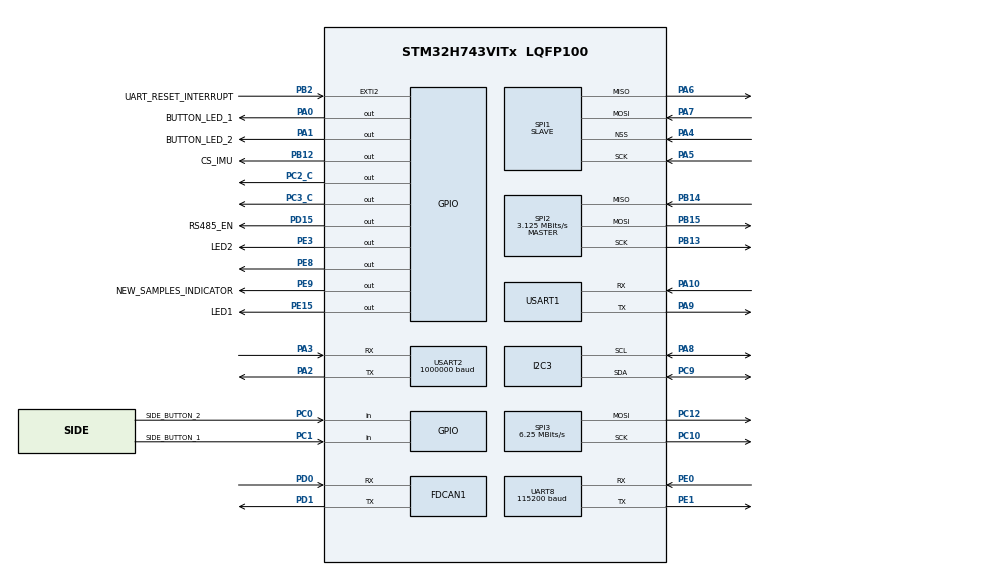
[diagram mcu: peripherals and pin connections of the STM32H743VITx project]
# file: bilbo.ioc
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CORTEX_M7.default_mode_Activation=0
Dma.MEMTOMEM.6.Direction=DMA_MEMORY_TO_MEMORY
Dma.MEMTOMEM.6.EventEnable=DISABLE
Dma.MEMTOMEM.6.FIFOMode=DMA_FIFOMODE_ENABLE
Dma.MEMTOMEM.6.FIFOThreshold=DMA_FIFO_THRESHOLD_FULL
Dma.MEMTOMEM.6.Instance=DMA2_Stream0
Dma.MEMTOMEM.6.MemBurst=DMA_MBURST_SINGLE
Dma.MEMTOMEM.6.MemDataAlignment=DMA_MDATAALIGN_BYTE
Dma.MEMTOMEM.6.MemInc=DMA_MINC_ENABLE
Dma.MEMTOMEM.6.Mode=DMA_NORMAL
Dma.MEMTOMEM.6.PeriphBurst=DMA_PBURST_SINGLE
Dma.MEMTOMEM.6.PeriphDataAlignment=DMA_PDATAALIGN_BYTE
Dma.MEMTOMEM.6.PeriphInc=DMA_PINC_ENABLE
Dma.MEMTOMEM.6.Polarity=HAL_DMAMUX_REQ_GEN_RISING
Dma.MEMTOMEM.6.Priority=DMA_PRIORITY_VERY_HIGH
Dma.MEMTOMEM.6.RequestNumber=1
Dma.MEMTOMEM.6.SignalID=NONE
Dma.MEMTOMEM.6.SyncEnable=DISABLE
Dma.MEMTOMEM.6.SyncPolarity=HAL_DMAMUX_SYNC_NO_EVENT
Dma.MEMTOMEM.6.SyncRequestNumber=1
Dma.MEMTOMEM.6.SyncSignalID=NONE
Dma.MEMTOMEM.9.Direction=DMA_MEMORY_TO_MEMORY
Dma.MEMTOMEM.9.EventEnable=DISABLE
Dma.MEMTOMEM.9.FIFOMode=DMA_FIFOMODE_ENABLE
Dma.MEMTOMEM.9.FIFOThreshold=DMA_FIFO_THRESHOLD_FULL
Dma.MEMTOMEM.9.Instance=DMA2_Stream1
Dma.MEMTOMEM.9.MemBurst=DMA_MBURST_SINGLE
Dma.MEMTOMEM.9.MemDataAlignment=DMA_MDATAALIGN_BYTE
Dma.MEMTOMEM.9.MemInc=DMA_MINC_ENABLE
Dma.MEMTOMEM.9.Mode=DMA_NORMAL
Dma.MEMTOMEM.9.PeriphBurst=DMA_PBURST_SINGLE
Dma.MEMTOMEM.9.PeriphDataAlignment=DMA_PDATAALIGN_BYTE
Dma.MEMTOMEM.9.PeriphInc=DMA_PINC_ENABLE
Dma.MEMTOMEM.9.Polarity=HAL_DMAMUX_REQ_GEN_RISING
Dma.MEMTOMEM.9.Priority=DMA_PRIORITY_HIGH
Dma.MEMTOMEM.9.RequestNumber=1
Dma.MEMTOMEM.9.SignalID=NONE
Dma.MEMTOMEM.9.SyncEnable=DISABLE
Dma.MEMTOMEM.9.SyncPolarity=HAL_DMAMUX_SYNC_NO_EVENT
Dma.MEMTOMEM.9.SyncRequestNumber=1
Dma.MEMTOMEM.9.SyncSignalID=NONE
Dma.Request0=USART1_RX
Dma.Request1=USART1_TX
Dma.Request2=UART8_RX
Dma.Request3=UART8_TX
Dma.Request4=USART2_RX
Dma.Request5=USART2_TX
Dma.Request6=MEMTOMEM
Dma.Request7=SPI1_RX
Dma.Request8=SPI1_TX
Dma.Request9=MEMTOMEM
Dma.SPI1_RX.7.Direction=DMA_PERIPH_TO_MEMORY
Dma.SPI1_RX.7.EventEnable=DISABLE
Dma.SPI1_RX.7.FIFOMode=DMA_FIFOMODE_DISABLE
Dma.SPI1_RX.7.Instance=DMA1_Stream6
Dma.SPI1_RX.7.MemDataAlignment=DMA_MDATAALIGN_BYTE
Dma.SPI1_RX.7.MemInc=DMA_MINC_ENABLE
Dma.SPI1_RX.7.Mode=DMA_NORMAL
Dma.SPI1_RX.7.PeriphDataAlignment=DMA_PDATAALIGN_BYTE
Dma.SPI1_RX.7.PeriphInc=DMA_PINC_DISABLE
Dma.SPI1_RX.7.Polarity=HAL_DMAMUX_REQ_GEN_RISING
Dma.SPI1_RX.7.Priority=DMA_PRIORITY_LOW
Dma.SPI1_RX.7.RequestNumber=1
Dma.SPI1_RX.7.SignalID=NONE
Dma.SPI1_RX.7.SyncEnable=DISABLE
Dma.SPI1_RX.7.SyncPolarity=HAL_DMAMUX_SYNC_NO_EVENT
Dma.SPI1_RX.7.SyncRequestNumber=1
Dma.SPI1_RX.7.SyncSignalID=NONE
Dma.SPI1_TX.8.Direction=DMA_MEMORY_TO_PERIPH
Dma.SPI1_TX.8.EventEnable=DISABLE
Dma.SPI1_TX.8.FIFOMode=DMA_FIFOMODE_DISABLE
Dma.SPI1_TX.8.Instance=DMA1_Stream7
Dma.SPI1_TX.8.MemDataAlignment=DMA_MDATAALIGN_BYTE
Dma.SPI1_TX.8.MemInc=DMA_MINC_ENABLE
Dma.SPI1_TX.8.Mode=DMA_NORMAL
Dma.SPI1_TX.8.PeriphDataAlignment=DMA_PDATAALIGN_BYTE
Dma.SPI1_TX.8.PeriphInc=DMA_PINC_DISABLE
Dma.SPI1_TX.8.Polarity=HAL_DMAMUX_REQ_GEN_RISING
Dma.SPI1_TX.8.Priority=DMA_PRIORITY_LOW
Dma.SPI1_TX.8.RequestNumber=1
Dma.SPI1_TX.8.SignalID=NONE
Dma.SPI1_TX.8.SyncEnable=DISABLE
Dma.SPI1_TX.8.SyncPolarity=HAL_DMAMUX_SYNC_NO_EVENT
Dma.SPI1_TX.8.SyncRequestNumber=1
Dma.SPI1_TX.8.SyncSignalID=NONE
Dma.UART8_RX.2.Direction=DMA_PERIPH_TO_MEMORY
Dma.UART8_RX.2.EventEnable=DISABLE
Dma.UART8_RX.2.FIFOMode=DMA_FIFOMODE_DISABLE
Dma.UART8_RX.2.Instance=DMA1_Stream2
Dma.UART8_RX.2.MemDataAlignment=DMA_MDATAALIGN_BYTE
Dma.UART8_RX.2.MemInc=DMA_MINC_ENABLE
Dma.UART8_RX.2.Mode=DMA_NORMAL
Dma.UART8_RX.2.PeriphDataAlignment=DMA_PDATAALIGN_BYTE
Dma.UART8_RX.2.PeriphInc=DMA_PINC_DISABLE
Dma.UART8_RX.2.Polarity=HAL_DMAMUX_REQ_GEN_RISING
Dma.UART8_RX.2.Priority=DMA_PRIORITY_HIGH
Dma.UART8_RX.2.RequestNumber=1
Dma.UART8_RX.2.SignalID=NONE
Dma.UART8_RX.2.SyncEnable=DISABLE
Dma.UART8_RX.2.SyncPolarity=HAL_DMAMUX_SYNC_NO_EVENT
Dma.UART8_RX.2.SyncRequestNumber=1
Dma.UART8_RX.2.SyncSignalID=NONE
Dma.UART8_TX.3.Direction=DMA_MEMORY_TO_PERIPH
Dma.UART8_TX.3.EventEnable=DISABLE
Dma.UART8_TX.3.FIFOMode=DMA_FIFOMODE_DISABLE
Dma.UART8_TX.3.Instance=DMA1_Stream3
Dma.UART8_TX.3.MemDataAlignment=DMA_MDATAALIGN_BYTE
Dma.UART8_TX.3.MemInc=DMA_MINC_ENABLE
Dma.UART8_TX.3.Mode=DMA_NORMAL
Dma.UART8_TX.3.PeriphDataAlignment=DMA_PDATAALIGN_BYTE
Dma.UART8_TX.3.PeriphInc=DMA_PINC_DISABLE
Dma.UART8_TX.3.Polarity=HAL_DMAMUX_REQ_GEN_RISING
Dma.UART8_TX.3.Priority=DMA_PRIORITY_LOW
Dma.UART8_TX.3.RequestNumber=1
Dma.UART8_TX.3.SignalID=NONE
Dma.UART8_TX.3.SyncEnable=DISABLE
Dma.UART8_TX.3.SyncPolarity=HAL_DMAMUX_SYNC_NO_EVENT
Dma.UART8_TX.3.SyncRequestNumber=1
Dma.UART8_TX.3.SyncSignalID=NONE
Dma.USART1_RX.0.Direction=DMA_PERIPH_TO_MEMORY
Dma.USART1_RX.0.EventEnable=DISABLE
Dma.USART1_RX.0.FIFOMode=DMA_FIFOMODE_DISABLE
Dma.USART1_RX.0.Instance=DMA1_Stream0
Dma.USART1_RX.0.MemDataAlignment=DMA_MDATAALIGN_BYTE
Dma.USART1_RX.0.MemInc=DMA_MINC_ENABLE
Dma.USART1_RX.0.Mode=DMA_NORMAL
Dma.USART1_RX.0.PeriphDataAlignment=DMA_PDATAALIGN_BYTE
Dma.USART1_RX.0.PeriphInc=DMA_PINC_DISABLE
Dma.USART1_RX.0.Polarity=HAL_DMAMUX_REQ_GEN_RISING
Dma.USART1_RX.0.Priority=DMA_PRIORITY_LOW
Dma.USART1_RX.0.RequestNumber=1
Dma.USART1_RX.0.SignalID=NONE
Dma.USART1_RX.0.SyncEnable=DISABLE
Dma.USART1_RX.0.SyncPolarity=HAL_DMAMUX_SYNC_NO_EVENT
Dma.USART1_RX.0.SyncRequestNumber=1
Dma.USART1_RX.0.SyncSignalID=NONE
Dma.USART1_TX.1.Direction=DMA_MEMORY_TO_PERIPH
Dma.USART1_TX.1.EventEnable=DISABLE
Dma.USART1_TX.1.FIFOMode=DMA_FIFOMODE_DISABLE
Dma.USART1_TX.1.Instance=DMA1_Stream1
Dma.USART1_TX.1.MemDataAlignment=DMA_MDATAALIGN_BYTE
Dma.USART1_TX.1.MemInc=DMA_MINC_ENABLE
Dma.USART1_TX.1.Mode=DMA_NORMAL
Dma.USART1_TX.1.PeriphDataAlignment=DMA_PDATAALIGN_BYTE
Dma.USART1_TX.1.PeriphInc=DMA_PINC_DISABLE
Dma.USART1_TX.1.Polarity=HAL_DMAMUX_REQ_GEN_RISING
Dma.USART1_TX.1.Priority=DMA_PRIORITY_LOW
Dma.USART1_TX.1.RequestNumber=1
Dma.USART1_TX.1.SignalID=NONE
Dma.USART1_TX.1.SyncEnable=DISABLE
Dma.USART1_TX.1.SyncPolarity=HAL_DMAMUX_SYNC_NO_EVENT
Dma.USART1_TX.1.SyncRequestNumber=1
Dma.USART1_TX.1.SyncSignalID=NONE
Dma.USART2_RX.4.Direction=DMA_PERIPH_TO_MEMORY
Dma.USART2_RX.4.EventEnable=DISABLE
Dma.USART2_RX.4.FIFOMode=DMA_FIFOMODE_DISABLE
Dma.USART2_RX.4.Instance=DMA1_Stream4
Dma.USART2_RX.4.MemDataAlignment=DMA_MDATAALIGN_BYTE
Dma.USART2_RX.4.MemInc=DMA_MINC_ENABLE
Dma.USART2_RX.4.Mode=DMA_NORMAL
Dma.USART2_RX.4.PeriphDataAlignment=DMA_PDATAALIGN_BYTE
Dma.USART2_RX.4.PeriphInc=DMA_PINC_DISABLE
Dma.USART2_RX.4.Polarity=HAL_DMAMUX_REQ_GEN_RISING
Dma.USART2_RX.4.Priority=DMA_PRIORITY_LOW
Dma.USART2_RX.4.RequestNumber=1
Dma.USART2_RX.4.SignalID=NONE
Dma.USART2_RX.4.SyncEnable=DISABLE
Dma.USART2_RX.4.SyncPolarity=HAL_DMAMUX_SYNC_NO_EVENT
Dma.USART2_RX.4.SyncRequestNumber=1
Dma.USART2_RX.4.SyncSignalID=NONE
Dma.USART2_TX.5.Direction=DMA_MEMORY_TO_PERIPH
Dma.USART2_TX.5.EventEnable=DISABLE
Dma.USART2_TX.5.FIFOMode=DMA_FIFOMODE_DISABLE
Dma.USART2_TX.5.Instance=DMA1_Stream5
Dma.USART2_TX.5.MemDataAlignment=DMA_MDATAALIGN_BYTE
Dma.USART2_TX.5.MemInc=DMA_MINC_ENABLE
Dma.USART2_TX.5.Mode=DMA_NORMAL
Dma.USART2_TX.5.PeriphDataAlignment=DMA_PDATAALIGN_BYTE
Dma.USART2_TX.5.PeriphInc=DMA_PINC_DISABLE
Dma.USART2_TX.5.Polarity=HAL_DMAMUX_REQ_GEN_RISING
Dma.USART2_TX.5.Priority=DMA_PRIORITY_LOW
Dma.USART2_TX.5.RequestNumber=1
Dma.USART2_TX.5.SignalID=NONE
Dma.USART2_TX.5.SyncEnable=DISABLE
Dma.USART2_TX.5.SyncPolarity=HAL_DMAMUX_SYNC_NO_EVENT
Dma.USART2_TX.5.SyncRequestNumber=1
Dma.USART2_TX.5.SyncSignalID=NONE
FDCAN1.CalculateBaudRateNominal=1000000
FDCAN1.CalculateTimeBitNominal=1000
FDCAN1.CalculateTimeQuantumNominal=100.0
FDCAN1.FrameFormat=FDCAN_FRAME_CLASSIC
FDCAN1.NominalPrescaler=10
FDCAN1.NominalTimeSeg1=7
FDCAN1.NominalTimeSeg2=2
FDCAN1.RxFifo0ElmtsNbr=4
FDCAN1.RxFifo1ElmtsNbr=4
FDCAN1.TxBuffersNbr=28
FDCAN1.TxFifoQueueElmtsNbr=4
FREERTOS.Tasks01=defaultTask,24,128,StartDefaultTask,Default,NULL,Dynamic,NULL,NULL
FREERTOS.Timers01=myTimer02,Callback01,osTimerPeriodic,Default,NULL,Dynamic,NULL
FREERTOS.configTOTAL_HEAP_SIZE=120000
FREERTOS.configUSE_NEWLIB_REENTRANT=1
I2C3.I2C_Rise_Time=0
I2C3.Timing=0x10C0ECFF
Mcu.Family=STM32H7
Mcu.Name=STM32H743VITx
Mcu.Package=LQFP100
NVIC.DMA1_Stream0_IRQn=true\:5\:0\:false\:false\:true\:true\:false\:true\:true
NVIC.DMA1_Stream1_IRQn=true\:5\:0\:false\:false\:true\:true\:false\:true\:true
NVIC.DMA1_Stream2_IRQn=true\:5\:0\:false\:false\:true\:false\:false\:true\:true
NVIC.DMA1_Stream3_IRQn=true\:5\:0\:false\:false\:true\:true\:false\:true\:true
NVIC.DMA1_Stream4_IRQn=true\:5\:0\:false\:false\:true\:true\:false\:true\:true
NVIC.DMA1_Stream5_IRQn=true\:5\:0\:false\:false\:true\:true\:false\:true\:true
NVIC.DMA1_Stream6_IRQn=true\:5\:0\:false\:false\:true\:true\:false\:true\:true
NVIC.DMA1_Stream7_IRQn=true\:5\:0\:false\:false\:true\:true\:false\:true\:true
NVIC.DMA2_Stream0_IRQn=true\:5\:0\:false\:false\:true\:true\:true\:true\:true
NVIC.DMA2_Stream1_IRQn=true\:5\:0\:false\:false\:true\:true\:true\:true\:true
NVIC.EXTI2_IRQn=true\:5\:0\:false\:false\:true\:true\:true\:true\:true
NVIC.FDCAN1_IT0_IRQn=true\:5\:0\:false\:false\:true\:true\:true\:true\:true
NVIC.FDCAN1_IT1_IRQn=true\:5\:0\:false\:false\:true\:true\:true\:true\:true
NVIC.I2C3_ER_IRQn=true\:5\:0\:false\:false\:true\:true\:true\:true\:true
NVIC.I2C3_EV_IRQn=true\:5\:0\:false\:false\:true\:true\:true\:true\:true
NVIC.PriorityGroup=NVIC_PRIORITYGROUP_4
NVIC.SPI1_IRQn=true\:5\:0\:false\:false\:true\:true\:true\:true\:true
NVIC.TIM6_DAC_IRQn=true\:15\:0\:false\:false\:true\:false\:false\:true\:true
NVIC.TimeBase=TIM6_DAC_IRQn
NVIC.TimeBaseIP=TIM6
NVIC.UART8_IRQn=true\:5\:0\:false\:false\:true\:true\:true\:true\:true
NVIC.USART1_IRQn=true\:5\:0\:false\:false\:true\:true\:true\:true\:true
NVIC.USART2_IRQn=true\:5\:0\:false\:false\:true\:true\:true\:true\:true
PA0.GPIO_Label=BUTTON_LED_1
PA0.Signal=GPIO_Output
PA1.GPIO_Label=BUTTON_LED_2
PA1.Signal=GPIO_Output
PA10.Mode=Asynchronous
PA10.Signal=USART1_RX
PA13\ (JTMS/SWDIO).Mode=Serial_Wire
PA13\ (JTMS/SWDIO).Signal=DEBUG_JTMS-SWDIO
PA14\ (JTCK/SWCLK).Mode=Serial_Wire
PA14\ (JTCK/SWCLK).Signal=DEBUG_JTCK-SWCLK
PA2.Mode=Asynchronous
PA2.Signal=USART2_TX
PA3.Mode=Asynchronous
PA3.Signal=USART2_RX
PA4.GPIO_PuPd=GPIO_NOPULL
PA4.GPIO_Speed=GPIO_SPEED_FREQ_VERY_HIGH
PA4.Mode=NSS_Signal_Hard_Input
PA4.Signal=SPI1_NSS
PA5.GPIO_Speed=GPIO_SPEED_FREQ_VERY_HIGH
PA5.Mode=Full_Duplex_Slave
PA5.Signal=SPI1_SCK
PA6.GPIO_Speed=GPIO_SPEED_FREQ_VERY_HIGH
PA6.Mode=Full_Duplex_Slave
PA6.Signal=SPI1_MISO
PA7.GPIO_Speed=GPIO_SPEED_FREQ_VERY_HIGH
PA7.Mode=Full_Duplex_Slave
PA7.Signal=SPI1_MOSI
PA8.Mode=I2C
PA8.Signal=I2C3_SCL
PA9.Mode=Asynchronous
PA9.Signal=USART1_TX
PB12.GPIO_Label=CS_IMU
PB12.Signal=GPIO_Output
PB13.Mode=Full_Duplex_Master
PB13.Signal=SPI2_SCK
PB14.Mode=Full_Duplex_Master
PB14.Signal=SPI2_MISO
PB15.Mode=Full_Duplex_Master
PB15.Signal=SPI2_MOSI
PB2.GPIO_Label=UART_RESET_INTERRUPT
PB2.GPIO_ModeDefaultEXTI=GPIO_MODE_IT_RISING_FALLING
PB2.GPIO_PuPd=GPIO_PULLDOWN
PB2.Signal=GPXTI2
PC0.GPIO_Label=SIDE_BUTTON_2
PC0.GPIO_PuPd=GPIO_PULLUP
PC0.Signal=GPIO_Input
PC1.GPIO_Label=SIDE_BUTTON_1
PC1.GPIO_PuPd=GPIO_PULLUP
PC1.Signal=GPIO_Input
PC10.Mode=TX_Only_Simplex_Unidirect_Master
PC10.Signal=SPI3_SCK
PC12.Mode=TX_Only_Simplex_Unidirect_Master
PC12.Signal=SPI3_MOSI
PC2_C.Signal=GPIO_Output
PC3_C.Signal=GPIO_Output
PC9.Mode=I2C
PC9.Signal=I2C3_SDA
PD0.Mode=FDCAN_Activate
PD0.Signal=FDCAN1_RX
PD1.Mode=FDCAN_Activate
PD1.Signal=FDCAN1_TX
PD15.GPIO_Label=RS485_EN
PD15.Signal=GPIO_Output
PE0.Mode=Asynchronous
PE0.Signal=UART8_RX
PE1.Mode=Asynchronous
PE1.Signal=UART8_TX
PE15.GPIO_Label=LED1
PE15.Signal=GPIO_Output
PE3.GPIO_Label=LED2
PE3.Signal=GPIO_Output
PE8.Signal=GPIO_Output
PE9.GPIO_Label=NEW_SAMPLES_INDICATOR
PE9.GPIO_PuPd=GPIO_PULLDOWN
PE9.Signal=GPIO_Output
PH0-OSC_IN\ (PH0).Mode=HSE-External-Oscillator
PH0-OSC_IN\ (PH0).Signal=RCC_OSC_IN
PH1-OSC_OUT\ (PH1).Mode=HSE-External-Oscillator
PH1-OSC_OUT\ (PH1).Signal=RCC_OSC_OUT
ProjectManager.HeapSize=0x200
ProjectManager.StackSize=0x400
ProjectManager.TargetToolchain=STM32CubeIDE
RCC.ADCFreq_Value=100000000
RCC.APB1Freq_Value=100000000
RCC.APB2Freq_Value=100000000
RCC.APB3Freq_Value=100000000
RCC.APB4Freq_Value=100000000
RCC.CortexFreq_Value=400000000
RCC.D1PPRE=RCC_APB3_DIV2
RCC.D2PPRE1=RCC_APB1_DIV2
RCC.D2PPRE2=RCC_APB2_DIV2
RCC.D3PPRE=RCC_APB4_DIV2
RCC.DIVM1=2
RCC.DIVM2=2
RCC.DIVN1=64
RCC.DIVN2=64
RCC.DIVP2=8
RCC.DIVQ1=4
RCC.DIVQ2=8
RCC.FDCANCLockSelection=RCC_FDCANCLKSOURCE_PLL2
RCC.HCLKFreq_Value=200000000
RCC.HPRE=RCC_HCLK_DIV2
RCC.PLL2FRACN=0
RCC.PLLFRACN=0
RCC.PLLSourceVirtual=RCC_PLLSOURCE_HSE
RCC.PWR_Regulator_Voltage_Scale=PWR_REGULATOR_VOLTAGE_SCALE0
RCC.SYSCLKFreq_VALUE=400000000
RCC.SYSCLKSource=RCC_SYSCLKSOURCE_PLLCLK
RCC.USBFreq_Value=200000000
SPI1.DataSize=SPI_DATASIZE_8BIT
SPI1.Direction=SPI_DIRECTION_2LINES
SPI1.Mode=SPI_MODE_SLAVE
SPI1.VirtualNSS=VM_NSSHARD
SPI1.VirtualType=VM_SLAVE
SPI2.BaudRatePrescaler=SPI_BAUDRATEPRESCALER_64
SPI2.CalculateBaudRate=3.125 MBits/s
SPI2.DataSize=SPI_DATASIZE_8BIT
SPI2.Direction=SPI_DIRECTION_2LINES
SPI2.Mode=SPI_MODE_MASTER
SPI2.VirtualType=VM_MASTER
SPI3.BaudRatePrescaler=SPI_BAUDRATEPRESCALER_32
SPI3.CalculateBaudRate=6.25 MBits/s
SPI3.DataSize=SPI_DATASIZE_8BIT
SPI3.Direction=SPI_DIRECTION_2LINES_TXONLY
SPI3.Mode=SPI_MODE_MASTER
SPI3.VirtualType=VM_MASTER
UART8.BaudRate=115200
UART8.Parity=PARITY_EVEN
UART8.WordLength=WORDLENGTH_9B
USART1.VirtualMode-Asynchronous=VM_ASYNC
USART2.BaudRate=1000000
USART2.VirtualMode-Asynchronous=VM_ASYNC
VP_FREERTOS_VS_CMSIS_V2.Mode=CMSIS_V2
VP_MEMORYMAP_VS_MEMORYMAP.Mode=CurAppReg
VP_SYS_VS_tim6.Mode=TIM6
VP_TIM2_VS_ClockSourceINT.Mode=Internal
board=custom

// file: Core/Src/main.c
/* USER CODE BEGIN Header */
/**
 ******************************************************************************
 * @file           : main.c
 * @brief          : Main program body
 ******************************************************************************
 * @attention
 *
 * Copyright (c) 2023 STMicroelectronics.
 * All rights reserved.
 *
 * This software is licensed under terms that can be found in the LICENSE file
 * in the root directory of this software component.
 * If no LICENSE file comes with this software, it is provided AS-IS.
 *
 ******************************************************************************
 */
/* USER CODE END Header */
#include "main.h"
#include "FreeRTOS.h"
#include "cmsis_os2.h"

FDCAN_HandleTypeDef hfdcan1;

I2C_HandleTypeDef hi2c3;

SPI_HandleTypeDef hspi1;
SPI_HandleTypeDef hspi2;
SPI_HandleTypeDef hspi3;
DMA_HandleTypeDef hdma_spi1_rx;
DMA_HandleTypeDef hdma_spi1_tx;

TIM_HandleTypeDef htim2;

UART_HandleTypeDef huart8;
UART_HandleTypeDef huart1;
UART_HandleTypeDef huart2;
DMA_HandleTypeDef hdma_uart8_rx;
DMA_HandleTypeDef hdma_uart8_tx;
DMA_HandleTypeDef hdma_usart1_rx;
DMA_HandleTypeDef hdma_usart1_tx;
DMA_HandleTypeDef hdma_usart2_rx;
DMA_HandleTypeDef hdma_usart2_tx;

DMA_HandleTypeDef hdma_memtomem_dma2_stream0;
DMA_HandleTypeDef hdma_memtomem_dma2_stream1;
/* Definitions for defaultTask */
osThreadId_t defaultTaskHandle;
const osThreadAttr_t defaultTask_attributes = {
  .name = "defaultTask",
  .stack_size = 128 * 4,
  .priority = (osPriority_t) osPriorityNormal,
};
/* Definitions for myTimer02 */
osTimerId_t myTimer02Handle;
const osTimerAttr_t myTimer02_attributes = {
  .name = "myTimer02"
};

void SystemClock_Config(void);
static void MX_GPIO_Init(void);
static void MX_DMA_Init(void);
static void MX_USART1_UART_Init(void);
static void MX_SPI2_Init(void);
static void MX_UART8_Init(void);
static void MX_USART2_UART_Init(void);
static void MX_TIM2_Init(void);
static void MX_SPI1_Init(void);
static void MX_I2C3_Init(void);
static void MX_FDCAN1_Init(void);
static void MX_SPI3_Init(void);
void StartDefaultTask(void *argument);
void Callback01(void *argument);

/* USER CODE BEGIN PFP */

void MX_UART8_Init_Wrapper(void) {
    MX_UART8_Init();
}

/* USER CODE END PFP */

int main(void)
{

  /* MCU Configuration--------------------------------------------------------*/

  /* Reset of all peripherals, Initializes the Flash interface and the Systick. */
  HAL_Init();

  /* Configure the system clock */
  SystemClock_Config();

  /* Initialize all configured peripherals */
  MX_GPIO_Init();
  MX_DMA_Init();
  MX_USART1_UART_Init();
  MX_SPI2_Init();
  MX_UART8_Init();
  MX_USART2_UART_Init();
  MX_TIM2_Init();
  MX_SPI1_Init();
  MX_I2C3_Init();
  MX_FDCAN1_Init();
  MX_SPI3_Init();

  /* Init scheduler */
  osKernelInitialize();

  /* Create the timer(s) */
  /* creation of myTimer02 */
  myTimer02Handle = osTimerNew(Callback01, osTimerPeriodic, NULL, &myTimer02_attributes);

  /* USER CODE BEGIN RTOS_QUEUES */
	/* add queues, ... */
  firmware();
  /* USER CODE END RTOS_QUEUES */

  /* Create the thread(s) */
  /* creation of defaultTask */
  defaultTaskHandle = osThreadNew(StartDefaultTask, NULL, &defaultTask_attributes);

  /* Start scheduler */
  osKernelStart();

  /* We should never get here as control is now taken by the scheduler */

  /* Infinite loop */
	while (1) {

	}
}

void SystemClock_Config(void)
{
  RCC_OscInitTypeDef RCC_OscInitStruct = {0};
  RCC_ClkInitTypeDef RCC_ClkInitStruct = {0};

  /** Supply configuration update enable
  */
  HAL_PWREx_ConfigSupply(PWR_LDO_SUPPLY);

  /** Configure the main internal regulator output voltage
  */
  __HAL_PWR_VOLTAGESCALING_CONFIG(PWR_REGULATOR_VOLTAGE_SCALE0);

  while(!__HAL_PWR_GET_FLAG(PWR_FLAG_VOSRDY)) {}

  /** Initializes the RCC Oscillators according to the specified parameters
  * in the RCC_OscInitTypeDef structure.
  */
  RCC_OscInitStruct.OscillatorType = RCC_OSCILLATORTYPE_HSE;
  RCC_OscInitStruct.HSEState = RCC_HSE_ON;
  RCC_OscInitStruct.PLL.PLLState = RCC_PLL_ON;
  RCC_OscInitStruct.PLL.PLLSource = RCC_PLLSOURCE_HSE;
  RCC_OscInitStruct.PLL.PLLM = 2;
  RCC_OscInitStruct.PLL.PLLN = 64;
  RCC_OscInitStruct.PLL.PLLP = 2;
  RCC_OscInitStruct.PLL.PLLQ = 4;
  RCC_OscInitStruct.PLL.PLLR = 2;
  RCC_OscInitStruct.PLL.PLLRGE = RCC_PLL1VCIRANGE_3;
  RCC_OscInitStruct.PLL.PLLVCOSEL = RCC_PLL1VCOWIDE;
  RCC_OscInitStruct.PLL.PLLFRACN = 0;
  if (HAL_RCC_OscConfig(&RCC_OscInitStruct) != HAL_OK)
  {
    Error_Handler();
  }

  /** Initializes the CPU, AHB and APB buses clocks
  */
  RCC_ClkInitStruct.ClockType = RCC_CLOCKTYPE_HCLK|RCC_CLOCKTYPE_SYSCLK
                              |RCC_CLOCKTYPE_PCLK1|RCC_CLOCKTYPE_PCLK2
                              |RCC_CLOCKTYPE_D3PCLK1|RCC_CLOCKTYPE_D1PCLK1;
  RCC_ClkInitStruct.SYSCLKSource = RCC_SYSCLKSOURCE_PLLCLK;
  RCC_ClkInitStruct.SYSCLKDivider = RCC_SYSCLK_DIV1;
  RCC_ClkInitStruct.AHBCLKDivider = RCC_HCLK_DIV2;
  RCC_ClkInitStruct.APB3CLKDivider = RCC_APB3_DIV2;
  RCC_ClkInitStruct.APB1CLKDivider = RCC_APB1_DIV2;
  RCC_ClkInitStruct.APB2CLKDivider = RCC_APB2_DIV2;
  RCC_ClkInitStruct.APB4CLKDivider = RCC_APB4_DIV2;

  if (HAL_RCC_ClockConfig(&RCC_ClkInitStruct, FLASH_LATENCY_2) != HAL_OK)
  {
    Error_Handler();
  }
}

static void MX_FDCAN1_Init(void)
{

  hfdcan1.Instance = FDCAN1;
  hfdcan1.Init.FrameFormat = FDCAN_FRAME_CLASSIC;
  hfdcan1.Init.Mode = FDCAN_MODE_NORMAL;
  hfdcan1.Init.AutoRetransmission = DISABLE;
  hfdcan1.Init.TransmitPause = DISABLE;
  hfdcan1.Init.ProtocolException = DISABLE;
  hfdcan1.Init.NominalPrescaler = 10;
  hfdcan1.Init.NominalSyncJumpWidth = 1;
  hfdcan1.Init.NominalTimeSeg1 = 7;
  hfdcan1.Init.NominalTimeSeg2 = 2;
  hfdcan1.Init.DataPrescaler = 1;
  hfdcan1.Init.DataSyncJumpWidth = 1;
  hfdcan1.Init.DataTimeSeg1 = 1;
  hfdcan1.Init.DataTimeSeg2 = 1;
  hfdcan1.Init.MessageRAMOffset = 0;
  hfdcan1.Init.StdFiltersNbr = 0;
  hfdcan1.Init.ExtFiltersNbr = 0;
  hfdcan1.Init.RxFifo0ElmtsNbr = 4;
  hfdcan1.Init.RxFifo0ElmtSize = FDCAN_DATA_BYTES_8;
  hfdcan1.Init.RxFifo1ElmtsNbr = 4;
  hfdcan1.Init.RxFifo1ElmtSize = FDCAN_DATA_BYTES_8;
  hfdcan1.Init.RxBuffersNbr = 0;
  hfdcan1.Init.RxBufferSize = FDCAN_DATA_BYTES_8;
  hfdcan1.Init.TxEventsNbr = 0;
  hfdcan1.Init.TxBuffersNbr = 28;
  hfdcan1.Init.TxFifoQueueElmtsNbr = 4;
  hfdcan1.Init.TxFifoQueueMode = FDCAN_TX_FIFO_OPERATION;
  hfdcan1.Init.TxElmtSize = FDCAN_DATA_BYTES_8;
  if (HAL_FDCAN_Init(&hfdcan1) != HAL_OK)
  {
    Error_Handler();
  }

}

static void MX_I2C3_Init(void)
{

  hi2c3.Instance = I2C3;
  hi2c3.Init.Timing = 0x10C0ECFF;
  hi2c3.Init.OwnAddress1 = 0;
  hi2c3.Init.AddressingMode = I2C_ADDRESSINGMODE_7BIT;
  hi2c3.Init.DualAddressMode = I2C_DUALADDRESS_DISABLE;
  hi2c3.Init.OwnAddress2 = 0;
  hi2c3.Init.OwnAddress2Masks = I2C_OA2_NOMASK;
  hi2c3.Init.GeneralCallMode = I2C_GENERALCALL_DISABLE;
  hi2c3.Init.NoStretchMode = I2C_NOSTRETCH_DISABLE;
  if (HAL_I2C_Init(&hi2c3) != HAL_OK)
  {
    Error_Handler();
  }

  /** Configure Analogue filter
  */
  if (HAL_I2CEx_ConfigAnalogFilter(&hi2c3, I2C_ANALOGFILTER_ENABLE) != HAL_OK)
  {
    Error_Handler();
  }

  /** Configure Digital filter
  */
  if (HAL_I2CEx_ConfigDigitalFilter(&hi2c3, 0) != HAL_OK)
  {
    Error_Handler();
  }

}

static void MX_SPI1_Init(void)
{

  /* SPI1 parameter configuration*/
  hspi1.Instance = SPI1;
  hspi1.Init.Mode = SPI_MODE_SLAVE;
  hspi1.Init.Direction = SPI_DIRECTION_2LINES;
  hspi1.Init.DataSize = SPI_DATASIZE_8BIT;
  hspi1.Init.CLKPolarity = SPI_POLARITY_LOW;
  hspi1.Init.CLKPhase = SPI_PHASE_1EDGE;
  hspi1.Init.NSS = SPI_NSS_HARD_INPUT;
  hspi1.Init.FirstBit = SPI_FIRSTBIT_MSB;
  hspi1.Init.TIMode = SPI_TIMODE_DISABLE;
  hspi1.Init.CRCCalculation = SPI_CRCCALCULATION_DISABLE;
  hspi1.Init.CRCPolynomial = 0x0;
  hspi1.Init.NSSPMode = SPI_NSS_PULSE_DISABLE;
  hspi1.Init.NSSPolarity = SPI_NSS_POLARITY_LOW;
  hspi1.Init.FifoThreshold = SPI_FIFO_THRESHOLD_01DATA;
  hspi1.Init.TxCRCInitializationPattern = SPI_CRC_INITIALIZATION_ALL_ZERO_PATTERN;
  hspi1.Init.RxCRCInitializationPattern = SPI_CRC_INITIALIZATION_ALL_ZERO_PATTERN;
  hspi1.Init.MasterSSIdleness = SPI_MASTER_SS_IDLENESS_00CYCLE;
  hspi1.Init.MasterInterDataIdleness = SPI_MASTER_INTERDATA_IDLENESS_00CYCLE;
  hspi1.Init.MasterReceiverAutoSusp = SPI_MASTER_RX_AUTOSUSP_DISABLE;
  hspi1.Init.MasterKeepIOState = SPI_MASTER_KEEP_IO_STATE_DISABLE;
  hspi1.Init.IOSwap = SPI_IO_SWAP_DISABLE;
  if (HAL_SPI_Init(&hspi1) != HAL_OK)
  {
    Error_Handler();
  }

}

static void MX_SPI2_Init(void)
{

  /* SPI2 parameter configuration*/
  hspi2.Instance = SPI2;
  hspi2.Init.Mode = SPI_MODE_MASTER;
  hspi2.Init.Direction = SPI_DIRECTION_2LINES;
  hspi2.Init.DataSize = SPI_DATASIZE_8BIT;
  hspi2.Init.CLKPolarity = SPI_POLARITY_LOW;
  hspi2.Init.CLKPhase = SPI_PHASE_1EDGE;
  hspi2.Init.NSS = SPI_NSS_SOFT;
  hspi2.Init.BaudRatePrescaler = SPI_BAUDRATEPRESCALER_64;
  hspi2.Init.FirstBit = SPI_FIRSTBIT_MSB;
  hspi2.Init.TIMode = SPI_TIMODE_DISABLE;
  hspi2.Init.CRCCalculation = SPI_CRCCALCULATION_DISABLE;
  hspi2.Init.CRCPolynomial = 0x0;
  hspi2.Init.NSSPMode = SPI_NSS_PULSE_ENABLE;
  hspi2.Init.NSSPolarity = SPI_NSS_POLARITY_LOW;
  hspi2.Init.FifoThreshold = SPI_FIFO_THRESHOLD_01DATA;
  hspi2.Init.TxCRCInitializationPattern = SPI_CRC_INITIALIZATION_ALL_ZERO_PATTERN;
  hspi2.Init.RxCRCInitializationPattern = SPI_CRC_INITIALIZATION_ALL_ZERO_PATTERN;
  hspi2.Init.MasterSSIdleness = SPI_MASTER_SS_IDLENESS_00CYCLE;
  hspi2.Init.MasterInterDataIdleness = SPI_MASTER_INTERDATA_IDLENESS_00CYCLE;
  hspi2.Init.MasterReceiverAutoSusp = SPI_MASTER_RX_AUTOSUSP_DISABLE;
  hspi2.Init.MasterKeepIOState = SPI_MASTER_KEEP_IO_STATE_DISABLE;
  hspi2.Init.IOSwap = SPI_IO_SWAP_DISABLE;
  if (HAL_SPI_Init(&hspi2) != HAL_OK)
  {
    Error_Handler();
  }

}

static void MX_SPI3_Init(void)
{

  /* SPI3 parameter configuration*/
  hspi3.Instance = SPI3;
  hspi3.Init.Mode = SPI_MODE_MASTER;
  hspi3.Init.Direction = SPI_DIRECTION_2LINES_TXONLY;
  hspi3.Init.DataSize = SPI_DATASIZE_8BIT;
  hspi3.Init.CLKPolarity = SPI_POLARITY_LOW;
  hspi3.Init.CLKPhase = SPI_PHASE_1EDGE;
  hspi3.Init.NSS = SPI_NSS_SOFT;
  hspi3.Init.BaudRatePrescaler = SPI_BAUDRATEPRESCALER_32;
  hspi3.Init.FirstBit = SPI_FIRSTBIT_MSB;
  hspi3.Init.TIMode = SPI_TIMODE_DISABLE;
  hspi3.Init.CRCCalculation = SPI_CRCCALCULATION_DISABLE;
  hspi3.Init.CRCPolynomial = 0x0;
  hspi3.Init.NSSPMode = SPI_NSS_PULSE_ENABLE;
  hspi3.Init.NSSPolarity = SPI_NSS_POLARITY_LOW;
  hspi3.Init.FifoThreshold = SPI_FIFO_THRESHOLD_01DATA;
  hspi3.Init.TxCRCInitializationPattern = SPI_CRC_INITIALIZATION_ALL_ZERO_PATTERN;
  hspi3.Init.RxCRCInitializationPattern = SPI_CRC_INITIALIZATION_ALL_ZERO_PATTERN;
  hspi3.Init.MasterSSIdleness = SPI_MASTER_SS_IDLENESS_00CYCLE;
  hspi3.Init.MasterInterDataIdleness = SPI_MASTER_INTERDATA_IDLENESS_00CYCLE;
  hspi3.Init.MasterReceiverAutoSusp = SPI_MASTER_RX_AUTOSUSP_DISABLE;
  hspi3.Init.MasterKeepIOState = SPI_MASTER_KEEP_IO_STATE_DISABLE;
  hspi3.Init.IOSwap = SPI_IO_SWAP_DISABLE;
  if (HAL_SPI_Init(&hspi3) != HAL_OK)
  {
    Error_Handler();
  }

}

static void MX_TIM2_Init(void)
{

  TIM_ClockConfigTypeDef sClockSourceConfig = {0};
  TIM_MasterConfigTypeDef sMasterConfig = {0};

  htim2.Instance = TIM2;
  htim2.Init.Prescaler = 0;
  htim2.Init.CounterMode = TIM_COUNTERMODE_UP;
  htim2.Init.Period = 4294967295;
  htim2.Init.ClockDivision = TIM_CLOCKDIVISION_DIV1;
  htim2.Init.AutoReloadPreload = TIM_AUTORELOAD_PRELOAD_DISABLE;
  if (HAL_TIM_Base_Init(&htim2) != HAL_OK)
  {
    Error_Handler();
  }
  sClockSourceConfig.ClockSource = TIM_CLOCKSOURCE_INTERNAL;
  if (HAL_TIM_ConfigClockSource(&htim2, &sClockSourceConfig) != HAL_OK)
  {
    Error_Handler();
  }
  sMasterConfig.MasterOutputTrigger = TIM_TRGO_RESET;
  sMasterConfig.MasterSlaveMode = TIM_MASTERSLAVEMODE_DISABLE;
  if (HAL_TIMEx_MasterConfigSynchronization(&htim2, &sMasterConfig) != HAL_OK)
  {
    Error_Handler();
  }

}

static void MX_UART8_Init(void)
{

  huart8.Instance = UART8;
  huart8.Init.BaudRate = 115200;
  huart8.Init.WordLength = UART_WORDLENGTH_9B;
  huart8.Init.StopBits = UART_STOPBITS_1;
  huart8.Init.Parity = UART_PARITY_EVEN;
  huart8.Init.Mode = UART_MODE_TX_RX;
  huart8.Init.HwFlowCtl = UART_HWCONTROL_NONE;
  huart8.Init.OverSampling = UART_OVERSAMPLING_16;
  huart8.Init.OneBitSampling = UART_ONE_BIT_SAMPLE_DISABLE;
  huart8.Init.ClockPrescaler = UART_PRESCALER_DIV1;
  huart8.AdvancedInit.AdvFeatureInit = UART_ADVFEATURE_NO_INIT;
  if (HAL_UART_Init(&huart8) != HAL_OK)
  {
    Error_Handler();
  }
  if (HAL_UARTEx_SetTxFifoThreshold(&huart8, UART_TXFIFO_THRESHOLD_1_8) != HAL_OK)
  {
    Error_Handler();
  }
  if (HAL_UARTEx_SetRxFifoThreshold(&huart8, UART_RXFIFO_THRESHOLD_1_8) != HAL_OK)
  {
    Error_Handler();
  }
  if (HAL_UARTEx_DisableFifoMode(&huart8) != HAL_OK)
  {
    Error_Handler();
  }

}

static void MX_USART1_UART_Init(void)
{

  huart1.Instance = USART1;
  huart1.Init.BaudRate = 115200;
  huart1.Init.WordLength = UART_WORDLENGTH_8B;
  huart1.Init.StopBits = UART_STOPBITS_1;
  huart1.Init.Parity = UART_PARITY_NONE;
  huart1.Init.Mode = UART_MODE_TX_RX;
  huart1.Init.HwFlowCtl = UART_HWCONTROL_NONE;
  huart1.Init.OverSampling = UART_OVERSAMPLING_16;
  huart1.Init.OneBitSampling = UART_ONE_BIT_SAMPLE_DISABLE;
  huart1.Init.ClockPrescaler = UART_PRESCALER_DIV1;
  huart1.AdvancedInit.AdvFeatureInit = UART_ADVFEATURE_NO_INIT;
  if (HAL_UART_Init(&huart1) != HAL_OK)
  {
    Error_Handler();
  }
  if (HAL_UARTEx_SetTxFifoThreshold(&huart1, UART_TXFIFO_THRESHOLD_1_8) != HAL_OK)
  {
    Error_Handler();
  }
  if (HAL_UARTEx_SetRxFifoThreshold(&huart1, UART_RXFIFO_THRESHOLD_1_8) != HAL_OK)
  {
    Error_Handler();
  }
  if (HAL_UARTEx_DisableFifoMode(&huart1) != HAL_OK)
  {
    Error_Handler();
  }

}

static void MX_USART2_UART_Init(void)
{

  huart2.Instance = USART2;
  huart2.Init.BaudRate = 1000000;
  huart2.Init.WordLength = UART_WORDLENGTH_8B;
  huart2.Init.StopBits = UART_STOPBITS_1;
  huart2.Init.Parity = UART_PARITY_NONE;
  huart2.Init.Mode = UART_MODE_TX_RX;
  huart2.Init.HwFlowCtl = UART_HWCONTROL_NONE;
  huart2.Init.OverSampling = UART_OVERSAMPLING_16;
  huart2.Init.OneBitSampling = UART_ONE_BIT_SAMPLE_DISABLE;
  huart2.Init.ClockPrescaler = UART_PRESCALER_DIV1;
  huart2.AdvancedInit.AdvFeatureInit = UART_ADVFEATURE_NO_INIT;
  if (HAL_UART_Init(&huart2) != HAL_OK)
  {
    Error_Handler();
  }
  if (HAL_UARTEx_SetTxFifoThreshold(&huart2, UART_TXFIFO_THRESHOLD_1_8) != HAL_OK)
  {
    Error_Handler();
  }
  if (HAL_UARTEx_SetRxFifoThreshold(&huart2, UART_RXFIFO_THRESHOLD_1_8) != HAL_OK)
  {
    Error_Handler();
  }
  if (HAL_UARTEx_DisableFifoMode(&huart2) != HAL_OK)
  {
    Error_Handler();
  }

}

static void MX_DMA_Init(void)
{

  /* DMA controller clock enable */
  __HAL_RCC_DMA1_CLK_ENABLE();
  __HAL_RCC_DMA2_CLK_ENABLE();

  /* Configure DMA request hdma_memtomem_dma2_stream0 on DMA2_Stream0 */
  hdma_memtomem_dma2_stream0.Instance = DMA2_Stream0;
  hdma_memtomem_dma2_stream0.Init.Request = DMA_REQUEST_MEM2MEM;
  hdma_memtomem_dma2_stream0.Init.Direction = DMA_MEMORY_TO_MEMORY;
  hdma_memtomem_dma2_stream0.Init.PeriphInc = DMA_PINC_ENABLE;
  hdma_memtomem_dma2_stream0.Init.MemInc = DMA_MINC_ENABLE;
  hdma_memtomem_dma2_stream0.Init.PeriphDataAlignment = DMA_PDATAALIGN_BYTE;
  hdma_memtomem_dma2_stream0.Init.MemDataAlignment = DMA_MDATAALIGN_BYTE;
  hdma_memtomem_dma2_stream0.Init.Mode = DMA_NORMAL;
  hdma_memtomem_dma2_stream0.Init.Priority = DMA_PRIORITY_VERY_HIGH;
  hdma_memtomem_dma2_stream0.Init.FIFOMode = DMA_FIFOMODE_ENABLE;
  hdma_memtomem_dma2_stream0.Init.FIFOThreshold = DMA_FIFO_THRESHOLD_FULL;
  hdma_memtomem_dma2_stream0.Init.MemBurst = DMA_MBURST_SINGLE;
  hdma_memtomem_dma2_stream0.Init.PeriphBurst = DMA_PBURST_SINGLE;
  if (HAL_DMA_Init(&hdma_memtomem_dma2_stream0) != HAL_OK)
  {
    Error_Handler( );
  }

  /* Configure DMA request hdma_memtomem_dma2_stream1 on DMA2_Stream1 */
  hdma_memtomem_dma2_stream1.Instance = DMA2_Stream1;
  hdma_memtomem_dma2_stream1.Init.Request = DMA_REQUEST_MEM2MEM;
  hdma_memtomem_dma2_stream1.Init.Direction = DMA_MEMORY_TO_MEMORY;
  hdma_memtomem_dma2_stream1.Init.PeriphInc = DMA_PINC_ENABLE;
  hdma_memtomem_dma2_stream1.Init.MemInc = DMA_MINC_ENABLE;
  hdma_memtomem_dma2_stream1.Init.PeriphDataAlignment = DMA_PDATAALIGN_BYTE;
  hdma_memtomem_dma2_stream1.Init.MemDataAlignment = DMA_MDATAALIGN_BYTE;
  hdma_memtomem_dma2_stream1.Init.Mode = DMA_NORMAL;
  hdma_memtomem_dma2_stream1.Init.Priority = DMA_PRIORITY_HIGH;
  hdma_memtomem_dma2_stream1.Init.FIFOMode = DMA_FIFOMODE_ENABLE;
  hdma_memtomem_dma2_stream1.Init.FIFOThreshold = DMA_FIFO_THRESHOLD_FULL;
  hdma_memtomem_dma2_stream1.Init.MemBurst = DMA_MBURST_SINGLE;
  hdma_memtomem_dma2_stream1.Init.PeriphBurst = DMA_PBURST_SINGLE;
  if (HAL_DMA_Init(&hdma_memtomem_dma2_stream1) != HAL_OK)
  {
    Error_Handler( );
  }

  /* DMA interrupt init */
  /* DMA1_Stream0_IRQn interrupt configuration */
  HAL_NVIC_SetPriority(DMA1_Stream0_IRQn, 5, 0);
  HAL_NVIC_EnableIRQ(DMA1_Stream0_IRQn);
  /* DMA1_Stream1_IRQn interrupt configuration */
  HAL_NVIC_SetPriority(DMA1_Stream1_IRQn, 5, 0);
  HAL_NVIC_EnableIRQ(DMA1_Stream1_IRQn);
  /* DMA1_Stream2_IRQn interrupt configuration */
  HAL_NVIC_SetPriority(DMA1_Stream2_IRQn, 5, 0);
  HAL_NVIC_EnableIRQ(DMA1_Stream2_IRQn);
  /* DMA1_Stream3_IRQn interrupt configuration */
  HAL_NVIC_SetPriority(DMA1_Stream3_IRQn, 5, 0);
  HAL_NVIC_EnableIRQ(DMA1_Stream3_IRQn);
  /* DMA1_Stream4_IRQn interrupt configuration */
  HAL_NVIC_SetPriority(DMA1_Stream4_IRQn, 5, 0);
  HAL_NVIC_EnableIRQ(DMA1_Stream4_IRQn);
  /* DMA1_Stream5_IRQn interrupt configuration */
  HAL_NVIC_SetPriority(DMA1_Stream5_IRQn, 5, 0);
  HAL_NVIC_EnableIRQ(DMA1_Stream5_IRQn);
  /* DMA1_Stream6_IRQn interrupt configuration */
  HAL_NVIC_SetPriority(DMA1_Stream6_IRQn, 5, 0);
  HAL_NVIC_EnableIRQ(DMA1_Stream6_IRQn);
  /* DMA1_Stream7_IRQn interrupt configuration */
  HAL_NVIC_SetPriority(DMA1_Stream7_IRQn, 5, 0);
  HAL_NVIC_EnableIRQ(DMA1_Stream7_IRQn);
  /* DMA2_Stream0_IRQn interrupt configuration */
  HAL_NVIC_SetPriority(DMA2_Stream0_IRQn, 5, 0);
  HAL_NVIC_EnableIRQ(DMA2_Stream0_IRQn);
  /* DMA2_Stream1_IRQn interrupt configuration */
  HAL_NVIC_SetPriority(DMA2_Stream1_IRQn, 5, 0);
  HAL_NVIC_EnableIRQ(DMA2_Stream1_IRQn);

}

static void MX_GPIO_Init(void)
{
  GPIO_InitTypeDef GPIO_InitStruct = {0};

  /* GPIO Ports Clock Enable */
  __HAL_RCC_GPIOE_CLK_ENABLE();
  __HAL_RCC_GPIOH_CLK_ENABLE();
  __HAL_RCC_GPIOC_CLK_ENABLE();
  __HAL_RCC_GPIOA_CLK_ENABLE();
  __HAL_RCC_GPIOB_CLK_ENABLE();
  __HAL_RCC_GPIOD_CLK_ENABLE();

  /*Configure GPIO pin Output Level */
  HAL_GPIO_WritePin(GPIOE, LED2_Pin|GPIO_PIN_8|NEW_SAMPLES_INDICATOR_Pin|LED1_Pin, GPIO_PIN_RESET);

  /*Configure GPIO pin Output Level */
  HAL_GPIO_WritePin(GPIOC, GPIO_PIN_2|GPIO_PIN_3, GPIO_PIN_RESET);

  /*Configure GPIO pin Output Level */
  HAL_GPIO_WritePin(GPIOA, BUTTON_LED_1_Pin|BUTTON_LED_2_Pin, GPIO_PIN_RESET);

  /*Configure GPIO pin Output Level */
  HAL_GPIO_WritePin(CS_IMU_GPIO_Port, CS_IMU_Pin, GPIO_PIN_RESET);

  /*Configure GPIO pin Output Level */
  HAL_GPIO_WritePin(RS485_EN_GPIO_Port, RS485_EN_Pin, GPIO_PIN_RESET);

  /*Configure GPIO pins : LED2_Pin PE8 LED1_Pin */
  GPIO_InitStruct.Pin = LED2_Pin|GPIO_PIN_8|LED1_Pin;
  GPIO_InitStruct.Mode = GPIO_MODE_OUTPUT_PP;
  GPIO_InitStruct.Pull = GPIO_NOPULL;
  GPIO_InitStruct.Speed = GPIO_SPEED_FREQ_LOW;
  HAL_GPIO_Init(GPIOE, &GPIO_InitStruct);

  /*Configure GPIO pins : SIDE_BUTTON_2_Pin SIDE_BUTTON_1_Pin */
  GPIO_InitStruct.Pin = SIDE_BUTTON_2_Pin|SIDE_BUTTON_1_Pin;
  GPIO_InitStruct.Mode = GPIO_MODE_INPUT;
  GPIO_InitStruct.Pull = GPIO_PULLUP;
  HAL_GPIO_Init(GPIOC, &GPIO_InitStruct);

  /*Configure GPIO pins : PC2 PC3 */
  GPIO_InitStruct.Pin = GPIO_PIN_2|GPIO_PIN_3;
  GPIO_InitStruct.Mode = GPIO_MODE_OUTPUT_PP;
  GPIO_InitStruct.Pull = GPIO_NOPULL;
  GPIO_InitStruct.Speed = GPIO_SPEED_FREQ_LOW;
  HAL_GPIO_Init(GPIOC, &GPIO_InitStruct);

  /*Configure GPIO pins : BUTTON_LED_1_Pin BUTTON_LED_2_Pin */
  GPIO_InitStruct.Pin = BUTTON_LED_1_Pin|BUTTON_LED_2_Pin;
  GPIO_InitStruct.Mode = GPIO_MODE_OUTPUT_PP;
  GPIO_InitStruct.Pull = GPIO_NOPULL;
  GPIO_InitStruct.Speed = GPIO_SPEED_FREQ_LOW;
  HAL_GPIO_Init(GPIOA, &GPIO_InitStruct);

  /*Configure GPIO pin : UART_RESET_INTERRUPT_Pin */
  GPIO_InitStruct.Pin = UART_RESET_INTERRUPT_Pin;
  GPIO_InitStruct.Mode = GPIO_MODE_IT_RISING_FALLING;
  GPIO_InitStruct.Pull = GPIO_PULLDOWN;
  HAL_GPIO_Init(UART_RESET_INTERRUPT_GPIO_Port, &GPIO_InitStruct);

  /*Configure GPIO pin : NEW_SAMPLES_INDICATOR_Pin */
  GPIO_InitStruct.Pin = NEW_SAMPLES_INDICATOR_Pin;
  GPIO_InitStruct.Mode = GPIO_MODE_OUTPUT_PP;
  GPIO_InitStruct.Pull = GPIO_PULLDOWN;
  GPIO_InitStruct.Speed = GPIO_SPEED_FREQ_LOW;
  HAL_GPIO_Init(NEW_SAMPLES_INDICATOR_GPIO_Port, &GPIO_InitStruct);

  /*Configure GPIO pin : CS_IMU_Pin */
  GPIO_InitStruct.Pin = CS_IMU_Pin;
  GPIO_InitStruct.Mode = GPIO_MODE_OUTPUT_PP;
  GPIO_InitStruct.Pull = GPIO_NOPULL;
  GPIO_InitStruct.Speed = GPIO_SPEED_FREQ_LOW;
  HAL_GPIO_Init(CS_IMU_GPIO_Port, &GPIO_InitStruct);

  /*Configure GPIO pin : RS485_EN_Pin */
  GPIO_InitStruct.Pin = RS485_EN_Pin;
  GPIO_InitStruct.Mode = GPIO_MODE_OUTPUT_PP;
  GPIO_InitStruct.Pull = GPIO_NOPULL;
  GPIO_InitStruct.Speed = GPIO_SPEED_FREQ_LOW;
  HAL_GPIO_Init(RS485_EN_GPIO_Port, &GPIO_InitStruct);

  /*AnalogSwitch Config */
  HAL_SYSCFG_AnalogSwitchConfig(SYSCFG_SWITCH_PC2, SYSCFG_SWITCH_PC2_CLOSE);

  /*AnalogSwitch Config */
  HAL_SYSCFG_AnalogSwitchConfig(SYSCFG_SWITCH_PC3, SYSCFG_SWITCH_PC3_CLOSE);

  /*AnalogSwitch Config */
  HAL_SYSCFG_AnalogSwitchConfig(SYSCFG_SWITCH_PA0, SYSCFG_SWITCH_PA0_CLOSE);

  /*AnalogSwitch Config */
  HAL_SYSCFG_AnalogSwitchConfig(SYSCFG_SWITCH_PA1, SYSCFG_SWITCH_PA1_CLOSE);

  /* EXTI interrupt init*/
  HAL_NVIC_SetPriority(UART_RESET_INTERRUPT_EXTI_IRQn, 5, 0);
  HAL_NVIC_EnableIRQ(UART_RESET_INTERRUPT_EXTI_IRQn);

}

void StartDefaultTask(void *argument)
{
  /* USER CODE BEGIN 5 */
	/* Infinite loop */
	for (;;) {
//	  firmware_loop();
		osDelay(1000);

	}
  /* USER CODE END 5 */
}

/* Callback01 function */
void Callback01(void *argument)
{
}

void HAL_TIM_PeriodElapsedCallback(TIM_HandleTypeDef *htim)
{
  if (htim->Instance == TIM6)
  {
    HAL_IncTick();
  }
}

void Error_Handler(void)
{
	__disable_irq();
	while (1) {
	}
}
